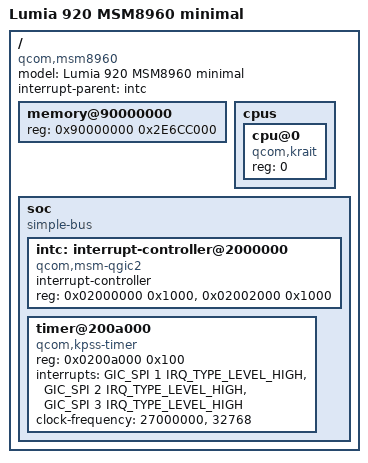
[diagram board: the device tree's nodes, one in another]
/dts-v1/;

#include <dt-bindings/interrupt-controller/arm-gic.h>

/ {
	model = "Lumia 920 MSM8960 minimal";
	compatible = "qcom,msm8960";

	interrupt-parent = <&intc>;

	#address-cells = <1>;
	#size-cells = <1>;

	memory@90000000 {
		device_type = "memory";
		reg = <0x90000000 0x2E6CC000>;
	};

	cpus {
		#address-cells = <1>;
		#size-cells = <0>;

		cpu@0 {
			device_type = "cpu";
			compatible = "qcom,krait";
			reg = <0>;
		};
	};


	soc {
		compatible = "simple-bus";
		#address-cells = <1>;
		#size-cells = <1>;
		ranges;


		intc: interrupt-controller@2000000 {
			compatible = "qcom,msm-qgic2";

			interrupt-controller;
			#interrupt-cells = <3>;

			reg =
				<0x02000000 0x1000>,
				<0x02002000 0x1000>;
		};


		timer@200a000 {
			compatible =
				"qcom,kpss-timer",
				"qcom,msm-timer";

			reg = <0x0200a000 0x100>;

			interrupts =
				<GIC_SPI 1 IRQ_TYPE_LEVEL_HIGH>,
				<GIC_SPI 2 IRQ_TYPE_LEVEL_HIGH>,
				<GIC_SPI 3 IRQ_TYPE_LEVEL_HIGH>;

			clock-frequency =
				<27000000>,
				<32768>;
		};
	};
};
